# CH32V30X register map
Vendor: WCH Ltd.; File version: 1.0
Registers are 32-bit, read-write, reset 0x0 unless marked. A register's access mark holds for its fields unless they carry their own. Offsets are from the block's base; [hi:lo] are bit positions; {n}, {i} and the like mark numbered series.

## PFIC — Programmable Fast Interrupt Controller
Base 0xE000E000
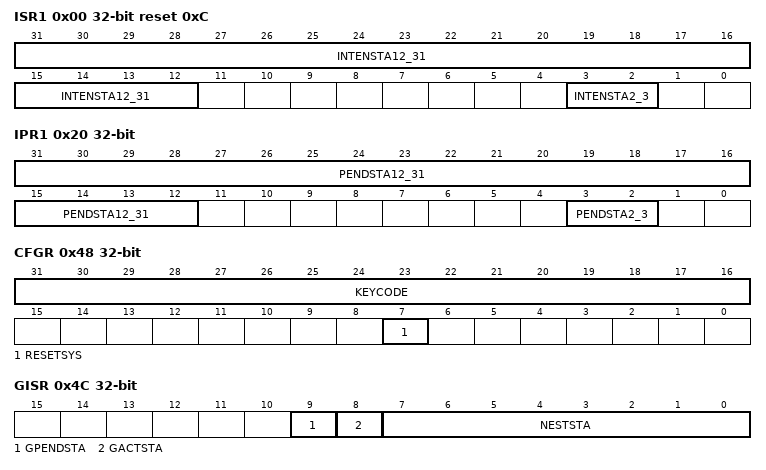
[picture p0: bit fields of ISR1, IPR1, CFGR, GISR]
0x00 ISR1 ro reset 0xC — Interrupt Status Register
  [31:12] INTENSTA12_31 — Interrupt ID Status
  [3:2] INTENSTA2_3 — Interrupt ID Status
0x04 ISR2 ro — Interrupt Status Register
  [31:0] INTENSTA — Interrupt ID Status
0x08 ISR3 ro — Interrupt Status Register
  [31:0] INTENSTA — Interrupt ID Status
0x0C ISR4 ro — Interrupt Status Register
  [7:0] INTENSTA — Interrupt ID Status
0x20 IPR1 ro — Interrupt Pending Register
  [31:12] PENDSTA12_31 — PENDSTA
  [3:2] PENDSTA2_3 — PENDSTA
0x24 IPR2 ro — Interrupt Pending Register
  [31:0] PENDSTA
0x28 IPR3 ro — Interrupt Pending Register
  [31:0] PENDSTA
0x2C IPR4 ro — Interrupt Pending Register
  [7:0] PENDSTA
0x40 ITHRESDR — Interrupt Priority Register
  [7:0] THRESHOLD
0x48 CFGR wo — Interrupt Config Register
  [31:16] KEYCODE, [7] RESETSYS
0x4C GISR ro — Interrupt Global Register
  [9] GPENDSTA, [8] GACTSTA, [7:0] NESTSTA
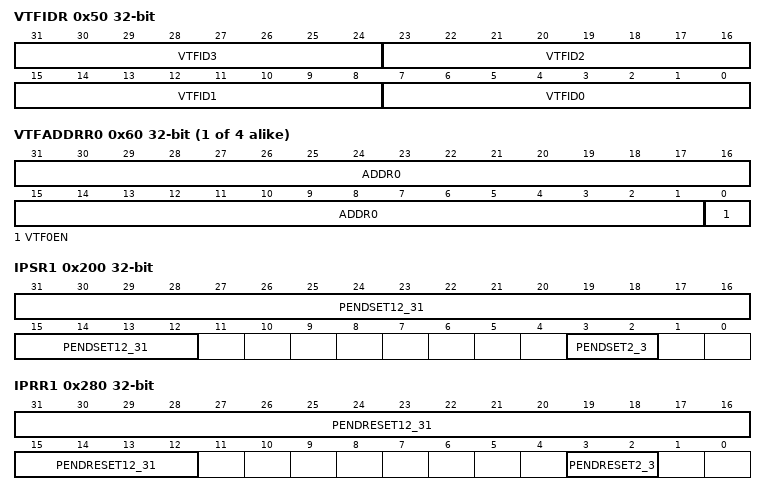
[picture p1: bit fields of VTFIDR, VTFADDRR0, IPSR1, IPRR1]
0x50 VTFIDR — ID Config Register
  [8n+7:8n] VTFID{n} (n=0..3)
{0x60+4i} VTFADDRR{i} (i=0..3) — Interrupt {i} address Register
  [31:1] ADDR{i}, [0] VTF{i}EN
0x100 IENR1 wo — Interrupt Setting Register
  [31:12] INTEN
0x104 IENR2 wo — Interrupt Setting Register
  [31:0] INTEN
0x108 IENR3 wo — Interrupt Setting Register
  [31:0] INTEN
0x10C IENR4 wo — Interrupt Setting Register
  [7:0] INTEN
0x180 IRER1 wo — Interrupt Clear Register
  [31:12] INTRSET
0x184 IRER2 wo — Interrupt Clear Register
  [31:0] INTRSET
0x188 IRER3 wo — Interrupt Clear Register
  [31:0] INTRSET
0x18C IRER4 wo — Interrupt Clear Register
  [7:0] INTRSET
0x200 IPSR1 wo — Interrupt Pending Register
  [31:12] PENDSET12_31 — PENDSET
  [3:2] PENDSET2_3 — PENDSET
0x204 IPSR2 wo — Interrupt Pending Register
  [31:0] PENDSET
0x208 IPSR3 wo — Interrupt Pending Register
  [31:0] PENDSET
0x20C IPSR4 wo — Interrupt Pending Register
  [7:0] PENDSET
0x280 IPRR1 wo — Interrupt Pending Clear Register
  [31:12] PENDRESET12_31 — PENDRESET
  [3:2] PENDRESET2_3 — PENDRESET
0x284 IPRR2 wo — Interrupt Pending Clear Register
  [31:0] PENDRESET
0x288 IPRR3 wo — Interrupt Pending Clear Register
  [31:0] PENDRESET
0x28C IPRR4 wo — Interrupt Pending Clear Register
  [7:0] PENDRESET
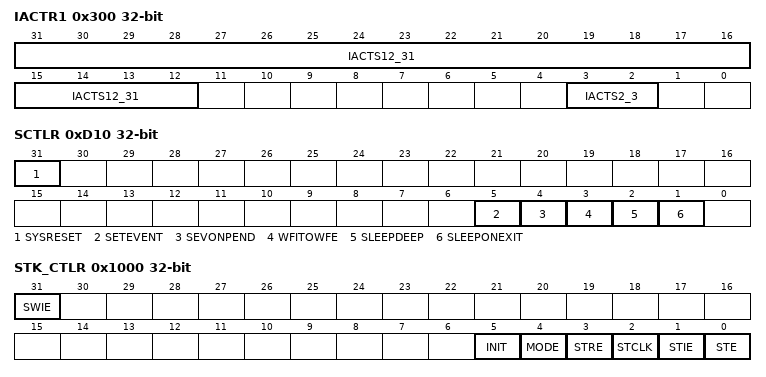
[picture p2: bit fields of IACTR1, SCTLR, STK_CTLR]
0x300 IACTR1 wo — Interrupt ACTIVE Register
  [31:12] IACTS12_31 — IACTS
  [3:2] IACTS2_3 — IACTS
0x304 IACTR2 wo — Interrupt ACTIVE Register
  [31:0] IACTS
0x308 IACTR3 wo — Interrupt ACTIVE Register
  [31:0] IACTS
0x30C IACTR4 wo — Interrupt ACTIVE Register
  [7:0] IACTS
{0x400+i} IPRIOR{i} 8-bit (i=0..255) — Interrupt Priority Register
0xD10 SCTLR — System Control Register
  [31] SYSRESET, [5] SETEVENT, [4] SEVONPEND, [3] WFITOWFE, [2] SLEEPDEEP, [1] SLEEPONEXIT
0x1000 STK_CTLR — System counter control register
  [31] SWIE — System software triggered interrupts enable
  [5] INIT — System Initialization update
  [4] MODE — System Mode
  [3] STRE — System reload register
  [2] STCLK — System selects the clock source
  [1] STIE — System counter interrupt enable
  [0] STE — System counter enable
0x1004 STK_SR — System START
  [0] CNTIF
0x1008 STK_CNTL — System counter low register
0x100C STK_CNTH — System counter high register
0x1010 STK_CMPLR — System compare low register
  [31:0] CMPL
0x1014 STK_CMPHR — System compare high register
  [31:0] CMPH

## SYSTICK — Systick registers, 64-bit downcounter for QingKeV4
Base 0xE000F000
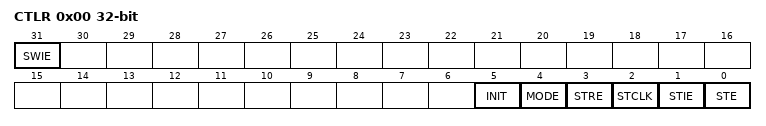
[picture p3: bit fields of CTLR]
0x00 CTLR — System count control register
  [31] SWIE — Software interrupt enable
  [5] INIT — Counter initial value update
  [4] MODE — Counter mode
    0=Upcount; 1=Downcount
  [3] STRE — Auto reload count enable bit
  [2] STCLK — Counter system clock sourse selection bit
    0=HCLK_DIV8 (HCLK/8); 1=HCLK
  [1] STIE — Counter interrupt enable control bit
  [0] STE — Counter enable control bit
0x04 SR — System count status register
  [0] CNTIF — Count value compare flag
0x08 CNT 64-bit (reset mask 0xFFFFFFFF) — System counter register
0x08 CNTL — System counter register, lower 32-bit
0x10 CMP 64-bit (reset mask 0xFFFFFFFF) — System count compare register
0x10 CMPL — System count compare register, lower 32-bit
